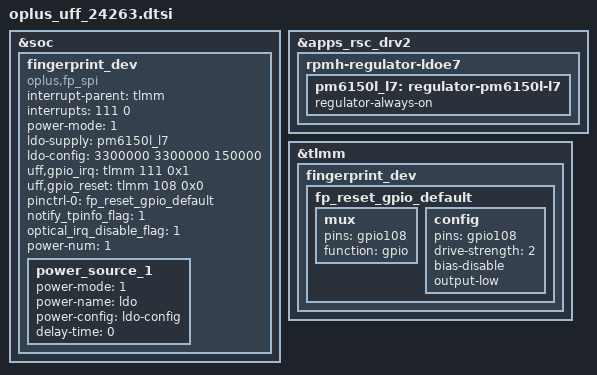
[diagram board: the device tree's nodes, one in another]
&soc {
	// #ifdef OPLUS_FEATURE_UFF_FINGERPRINT
	fingerprint_dev {
		status = "ok";
		compatible = "oplus,fp_spi";
		interrupt-parent = <&tlmm>;
		interrupts = <111 0>;
		power-mode = <1> ; /*0: power mode not set, 1: ldo power, 2: gpio power, 3: auto power */
		ldo-supply = <&pm6150l_l7>;
		ldo-config = <3300000 3300000 150000>;
		uff,gpio_irq = <&tlmm 111 0x1>;
		uff,gpio_reset = <&tlmm 108 0x0>;
		pinctrl-names = "default";
		pinctrl-0 = <&fp_reset_gpio_default>;
		notify_tpinfo_flag = <1>;
		optical_irq_disable_flag = <1>;
		power-num = <1>;
		power_source_1 {
			power-mode = <1>;
			power-name = "ldo";
			power-config = "ldo-config";
			delay-time = <0>;
		};
	};
	//#endif /*OPLUS_FEATURE_UFF_FINGERPRINT*/
};

&apps_rsc_drv2 {
		rpmh-regulator-ldoe7 {
		pm6150l_l7: regulator-pm6150l-l7 {
			regulator-always-on;
		};
	};

};

&tlmm {
	// #ifdef OPLUS_FEATURE_UFF_FINGERPRINT
	fingerprint_dev{
		fp_reset_gpio_default: fp_reset_gpio_default {
			mux {
				pins = "gpio108";
				function = "gpio";
			};
			config {
				pins = "gpio108";
				drive-strength = <2>;
				bias-disable;
				output-low;
			};
		};
	};
	//#endif /*OPLUS_FEATURE_UFF_FINGERPRINT*/
};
